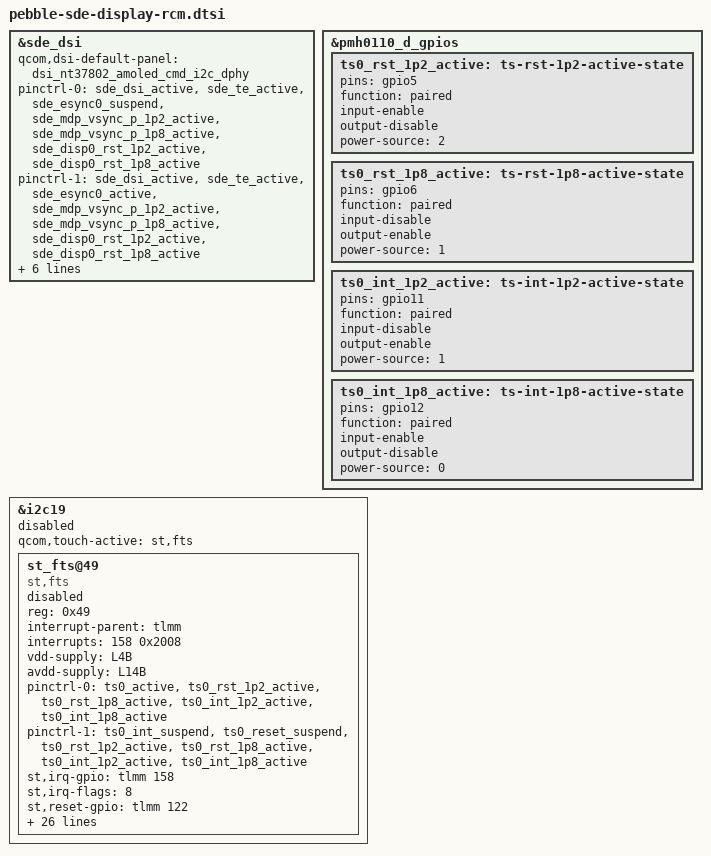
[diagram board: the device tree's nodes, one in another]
// SPDX-License-Identifier: BSD-3-Clause
/*
 * Copyright (c) Qualcomm Technologies, Inc. and/or its subsidiaries.
 */

#include "pebble-sde-display-mtp.dtsi"


&sde_dsi {
	qcom,dsi-default-panel = <&dsi_nt37802_amoled_cmd_i2c_dphy>;

	pinctrl-names = "panel_active", "panel_active_with_esync", "panel_suspend";
	pinctrl-0 = <&sde_dsi_active &sde_te_active &sde_esync0_suspend
			&sde_mdp_vsync_p_1p2_active &sde_mdp_vsync_p_1p8_active
			&sde_disp0_rst_1p2_active &sde_disp0_rst_1p8_active>;
	pinctrl-1 = <&sde_dsi_active &sde_te_active &sde_esync0_active
			&sde_mdp_vsync_p_1p2_active &sde_mdp_vsync_p_1p8_active
			&sde_disp0_rst_1p2_active &sde_disp0_rst_1p8_active>;
	pinctrl-2 = <&sde_dsi_suspend &sde_te_suspend &sde_esync0_suspend
			&sde_mdp_vsync_p_1p2_active &sde_mdp_vsync_p_1p8_active
			&sde_disp0_rst_1p2_active &sde_disp0_rst_1p8_active>;
};


&pmh0110_d_gpios {
	ts0_rst_1p2_active: ts-rst-1p2-active-state {
		pins = "gpio5";
		function = "paired";
		input-enable;
		output-disable;
		power-source = <2>; /* 1.2 V */
	};

	ts0_rst_1p8_active: ts-rst-1p8-active-state {
		pins = "gpio6";
		function = "paired";
		input-disable;
		output-enable;
		power-source = <1>; /* 1.8 V */
	};

	ts0_int_1p2_active: ts-int-1p2-active-state {
		pins = "gpio11";
		function = "paired";
		input-disable;
		output-enable;
		power-source = <1>; /* 1.2 V */
	};

	ts0_int_1p8_active: ts-int-1p8-active-state {
		pins = "gpio12";
		function = "paired";
		input-enable;
		output-disable;
		power-source = <0>; /* 1.8 V */
	};
};

&i2c19 {
	#address-cells = <1>;
	#size-cells = <0>;

	status = "disabled";
	qcom,touch-active = "st,fts";

	st_fts@49 {
		status = "disabled";
		compatible = "st,fts";
		reg = <0x49>;
		interrupt-parent = <&tlmm>;
		interrupts = <158 0x2008>;
		vdd-supply = <&L4B>;
		avdd-supply = <&L14B>;
		pinctrl-names = "pmx_ts_active", "pmx_ts_suspend";
		pinctrl-0 = <&ts0_active
				&ts0_rst_1p2_active &ts0_rst_1p8_active
				&ts0_int_1p2_active &ts0_int_1p8_active>;
		pinctrl-1 = <&ts0_int_suspend &ts0_reset_suspend
				&ts0_rst_1p2_active &ts0_rst_1p8_active
				&ts0_int_1p2_active &ts0_int_1p8_active>;
		st,irq-gpio = <&tlmm 158 0x2008>;
		st,irq-flags = <8>;
		st,reset-gpio = <&tlmm 122 0x00>;
		st,regulator_dvdd = "vdd";
		st,regulator_avdd = "avdd";

		st,touch-type = "primary";
		st,qts_en;
		qts,trusted-touch-mode = "vm_mode";
		qts,touch-environment = "pvm";
		qts,trusted-touch-type = "primary";
		qts,trusted-touch-spi-irq = <408>;
		qts,trusted-touch-io-bases = <0x1a80000>;
		qts,trusted-touch-io-sizes = <0x1000>;
		qts,trusted-touch-vm-gpio-list = <&tlmm 48 0 &tlmm 49 0 &tlmm 50 0
						&tlmm 51 0 &tlmm 122 0 &tlmm 158 0x2008>;

		panel = <&dsi_nt37801_amoled_cmd
			&dsi_nt37801_amoled_cmd_cphy
			&dsi_nt37801_amoled_video
			&dsi_nt37801_amoled_video_cphy
			&dsi_nt37801_amoled_dsc_10b_cmd
			&dsi_nt37801_amoled_dsc_10b_video
			&dsi_nt37801_amoled_cmd_spr
			&dsi_nt37801_amoled_vid_spr
			&dsi_nt37801_amoled_qsync_cmd
			&dsi_nt37801_amoled_qsync_video
			&dsi_nt37801_amoled_fhd_plus_cmd
			&dsi_nt37801_amoled_cmd_ddicspr
			&dsi_nt37801_amoled_video_ddicspr>;
	};
};
